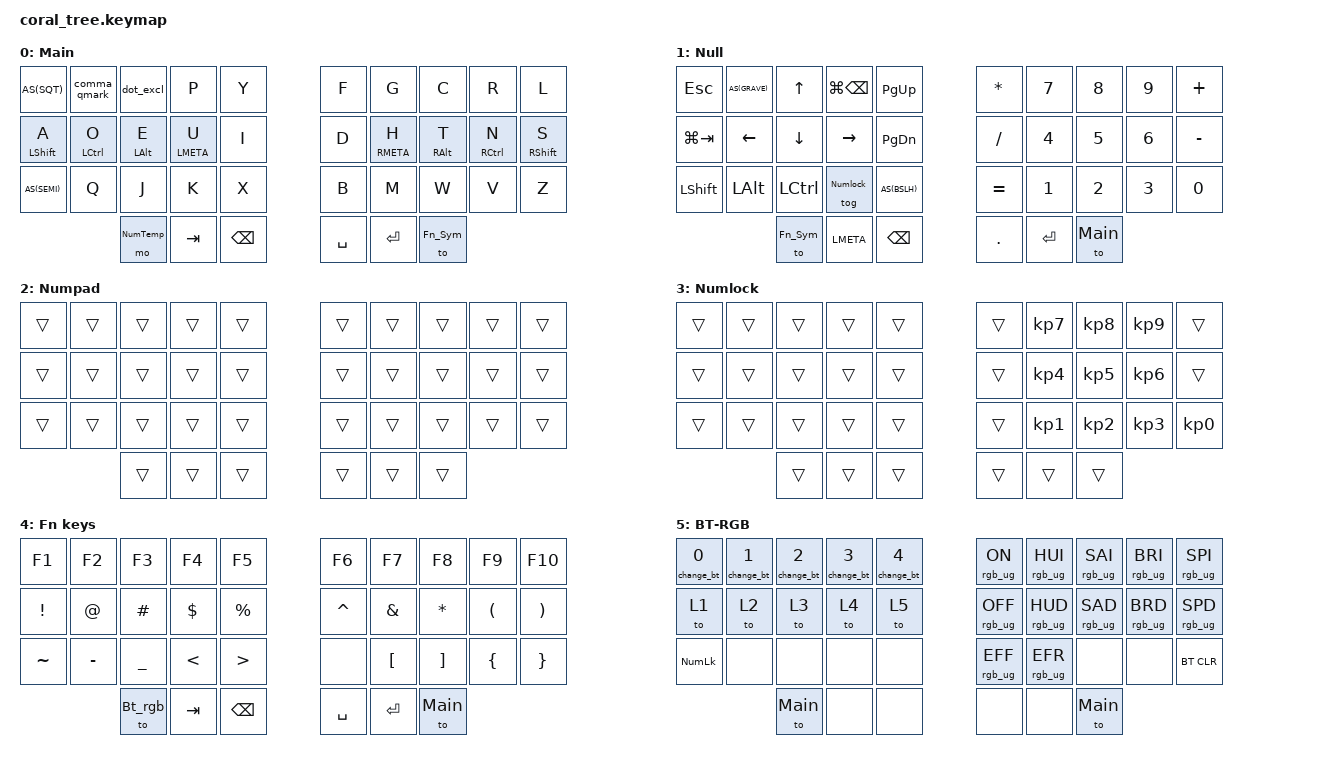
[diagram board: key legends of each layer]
/*
 * Copyright (c) 2020 The ZMK Contributors
 *
 * SPDX-License-Identifier: MIT
 */

#include <behaviors.dtsi>
#include <dt-bindings/zmk/keys.h>
#include <dt-bindings/zmk/bt.h>
#include <dt-bindings/zmk/rgb.h>

#define AS(keycode) &as LS(keycode) keycode     // Autoshift Macro

#define Main    0
#define Numpad  1
#define NumTemp 2
#define Numlock 3
#define Fn_Sym  4
#define Bt_rgb  5

/ {
    macros {
        change_bt: change_bt {
            compatible = "zmk,behavior-macro-one-param";
            #binding-cells = <1>; 
            bindings = <&macro_param_1to2> 
                     , <&bt BT_SEL MACRO_PLACEHOLDER>
                     , <&to Main>;
        };
    };
    conditional_layers {
        compatible = "zmk,conditional-layers";
        numeric_momentary {
            if-layers = <NumTemp>;
            then-layer = <Numpad>;
        };
        numeric_hold {
            if-layers = <Numlock>;
            then-layer = <Numpad>;
        };
    };
    behaviors {
        tog_on: toggle_layer_on_only {
            compatible = "zmk,behavior-toggle-layer";
            #binding-cells = <1>;
            display-name = "Toggle Layer On";
            toggle-mode = "on";
        };
        as: auto_shift {
            compatible = "zmk,behavior-hold-tap";
            #binding-cells = <2>;
            tapping_term_ms = <300>;
            quick_tap_ms = <0>;
            flavor = "tap-preferred";
            bindings = <&kp>, <&kp>;
        };
        hm: homerow_mods {
            compatible = "zmk,behavior-hold-tap";
            #binding-cells = <2>;
            tapping-term-ms = <300>;
            flavor = "balanced";
            bindings = <&kp>, <&kp>;
        };
        dot_excl: dot_exclamation {
            compatible = "zmk,behavior-mod-morph";
            #binding-cells = <0>;
            bindings = <&kp DOT>, <&kp EXCL>;
            mods = <(MOD_LSFT|MOD_RSFT)>;
        };
        comma_qmark: comma_question {
            compatible = "zmk,behavior-mod-morph";
            #binding-cells = <0>;
            bindings = <&kp COMMA>, <&kp QMARK>;
            mods = <(MOD_LSFT|MOD_RSFT)>;
        };
    };
    keymap {
        compatible = "zmk,keymap";

    main_layer {
    // -----------------------------------------------------------------------------------------
    // | ' " | , ? | . ! |  P  |  Y  |   |  F  |  G  |  C  |  R  |  L  |
    // | s A | c O | a E | m U |  I  |   |  D  | m H | a T | c N | s S |
    // | ; : |  Q  |  J  |  K  |  X  |   |  B  |  M  |  W  |  V  |  Z  | 
    //             | Num | Tab | Bck |   | Fn  | Spc | Ret |
    bindings = <
        AS(SQT)       &comma_qmark  &dot_excl    &kp P        &kp Y     /**/  &kp F      &kp G        &kp C       &kp R       &kp L
        &hm LSHIFT A  &hm LCTL O    &hm LALT E   &hm LMETA U  &kp I     /**/  &kp D      &hm RMETA H  &hm RALT T  &hm RCTL N  &hm RSHIFT S
        AS(SEMI)      &kp Q         &kp J        &kp K        &kp X     /**/  &kp B      &kp M        &kp W       &kp V       &kp Z
                                    &mo NumTemp  &kp TAB      &kp BSPC  /**/  &kp SPACE  &kp RET      &to Fn_Sym      
        >;
    display-name = "Main";
    };

    numpad_layer {
    // -----------------------------------------------------------------------------------------
    // | ESC | GRV |  Up | M(B)| p_u | /**/ |  *  |  7  |  8  |  9  |  +  |
    // | TAB | Lef | Dwn | Rgt | p_d | /**/ |  /  |  4  |  5  |  6  |  -  | 
    // |Lshft| Lalt|Lctrl| NumL|  \  | /**/ |  =  |  1  |  2  |  3  |  0  |
    //             | Fn  |Lmeta| Bck | /**/ |  .  | trn | RET |
    bindings = <
        &kp ESC      AS(GRAVE)  &kp UP      &kp LG(BSPC)  &kp PG_UP  /**/  &kp STAR   &kp N7     &kp N8    &kp N9  &kp PLUS
        &kp LG(TAB)  &kp LEFT   &kp DOWN    &kp RIGHT     &kp PG_DN  /**/  &kp FSLH   &kp N4     &kp N5    &kp N6  &kp MINUS
        &kp LSHFT    &kp LALT   &kp LCTRL   &tog Numlock  AS(BSLH)   /**/  &kp EQUAL  &kp N1     &kp N2    &kp N3  &kp N0
                                &to Fn_Sym  &kp LMETA     &kp BSPC   /**/  &kp DOT    &kp ENTER  &to Main        
    >;
    display-name = "Null";
    };

    numtemp_layer {
    // Allows for layer hold 
    bindings = <
  	&trans  &trans  &trans  &trans  &trans    &trans  &trans  &trans  &trans  &trans
  	&trans  &trans  &trans  &trans  &trans    &trans  &trans  &trans  &trans  &trans
  	&trans  &trans  &trans  &trans  &trans    &trans  &trans  &trans  &trans  &trans
        	        &trans  &trans  &trans    &trans  &trans  &trans
    >;
    display-name = "Numpad";
    };

    numlock_layer {
    // Layer hold
    bindings = <
  	&trans  &trans  &trans  &trans  &trans    &trans  &kp KP_N7  &kp KP_N8  &kp KP_N9  &trans
  	&trans  &trans  &trans  &trans  &trans    &trans  &kp KP_N4  &kp KP_N5  &kp KP_N6  &trans
  	&trans  &trans  &trans  &trans  &trans    &trans  &kp KP_N1  &kp KP_N2  &kp KP_N3  &kp KP_N0
        	        &trans  &trans  &trans    &trans  &trans     &trans
    >;
    display-name = "Numlock";
    };
                   
    fn_sym_layer {
    // -----------------------------------------------------------------------------------------
    // |  F1 |  F2 |  F3 |  F4 |  F5 | /**/ |  F6 |  F7 |  F8 |  F0 | F10 |
    // |  !  |  @  |  #  |  $  |  %  | /**/ |  ^  |  &  |  *  |  (  |  )  |
    // |  ~  |  -  |  _  |  <  |  >  | /**/ | non |  [  |  ]  |  {  |  }  |
    //             | ToBt| Tab | Bck | /**/ | SPC | RET | ToM |
    bindings = <
        &kp F1      &kp F2     &kp F3      &kp F4      &kp F5       /**/  &kp F6     &kp F7    &kp F8    &kp F9    &kp F10
        &kp EXCL    &kp AT     &kp HASH    &kp DOLLAR  &kp PERCENT  /**/  &kp CARET  &kp AMPS  &kp STAR  &kp LPAR  &kp RPAR
        &kp TILDE   &kp MINUS  &kp UNDER   &kp LT      &kp GT       /**/  &none      &kp LBKT  &kp RBKT  &kp LBRC  &kp RBRC
                               &to Bt_rgb  &kp TAB     &kp BSPC     /**/  &kp SPACE  &kp RET   &to Main        
    >;
    display-name = "Fn keys";
    };

    btrgb_layer {
    // -----------------------------------------------------------------------------------------
    // | BT0 | BT1 | BT2 | BT3 | BT4 | /**/ | ron |  F7 |  F8 |  F0 | F10 |
    // | to1 | to2 | to3 | to4 | to5 | /**/ |  ^  |  &  |  *  |  (  |  )  |
    // |NumLk| non | non | non | non | /**/ | non |  [  |  ]  |  {  |  }  |
    //             | non | non | ToM | /**/ | SPC | RET | ToM |
    bindings = <
        &change_bt 0  &change_bt 1  &change_bt 2  &change_bt 3  &change_bt 4  /**/  &rgb_ug RGB_ON   &rgb_ug RGB_HUI  &rgb_ug RGB_SAI  &rgb_ug RGB_BRI  &rgb_ug RGB_SPI
        &to 1         &to 2         &to 3         &to 4         &to 5         /**/  &rgb_ug RGB_OFF  &rgb_ug RGB_HUD  &rgb_ug RGB_SAD  &rgb_ug RGB_BRD  &rgb_ug RGB_SPD
        &kp KP_NUM    &none         &none         &none         &none         /**/  &rgb_ug RGB_EFF  &rgb_ug RGB_EFR  &none            &none            &bt BT_CLR 
                                    &to Main      &none         &none         /**/  &none            &none            &to Main
    >;
    display-name = "BT-RGB";
    };

  };
};
